# ECAP_ECAP_23100000h register map
Vendor: Texas Instruments
Peripheral module from a debugger description file (folder AM275x).
Registers are 32-bit, read-write, reset 0x0 unless marked. A register's access mark holds for its fields unless they carry their own. Offsets are as the file gives them; lines under a group give offsets from that group; [hi:lo] are bit positions; {n}, {i} and the like mark numbered series; 'fields as' and 'values as' point back to an identical list; <NAME> marks a mode.

## ecap
0x00 ECAP_TSCNT
  [31:0] TSCNT — Active 32 bit Counter register which is used as the Capture time-base Reset Source: vbus_rst_mod_g_rst_n
0x04 ECAP_CNTPHS
  [31:0] CNTPHS — Counter phase value register that can be programmed for phase Lag/Lead. This register shadows the ECAP_TSCNT register and is loaded into the ECAP_TSCNT register upon either a SYNCI event or software force via a control bit.Used to achieve phase control sync with respect to other ECAP and EPWM time-bases. Reset Source: vbus_rst_mod_g_rst_n
0x08 ECAP_CAP1
  [31:0] CAP1 — This register can be loaded (written) by:1. Time-Stamp (counter value) during a capture event.2. Software - may be useful for test purposes/initialisation.3. APRD shadow register (ECAP_CAP3) when used in APWM mode. Reset Source: vbus_rst_mod_g_rst_n
0x0C ECAP_CAP2
  [31:0] CAP2 — This register can be loaded (written) by:1. Time-Stamp (counter value) during a capture event.2. Software - may be useful for test purposes.3. ACMP shadow register (ECAP_CAP4) when used in APWM mode. Reset Source: vbus_rst_mod_g_rst_n
0x10 ECAP_CAP3
  [31:0] CAP3 — In CMP mode this is a time-stamp capture register.In APMW mode this is the period shadow (APER) register.User updates the PWM period value via this register.In this mode the ECAP_CAP3 (APRD) register shadows the ECAP_CAP1 register. Reset Source: vbus_rst_mod_g_rst_n
0x14 ECAP_CAP4
  [31:0] CAP4 — In CMP mode this is a time-stamp capture register.In APMW mode this is the compare shadow (ACMP) register.User updates the PWM Compare value via this register.In this mode the ECAP_CAP4 (ACMP) register shadows the ECAP_CAP2 register. Reset Source: vbus_rst_mod_g_rst_n
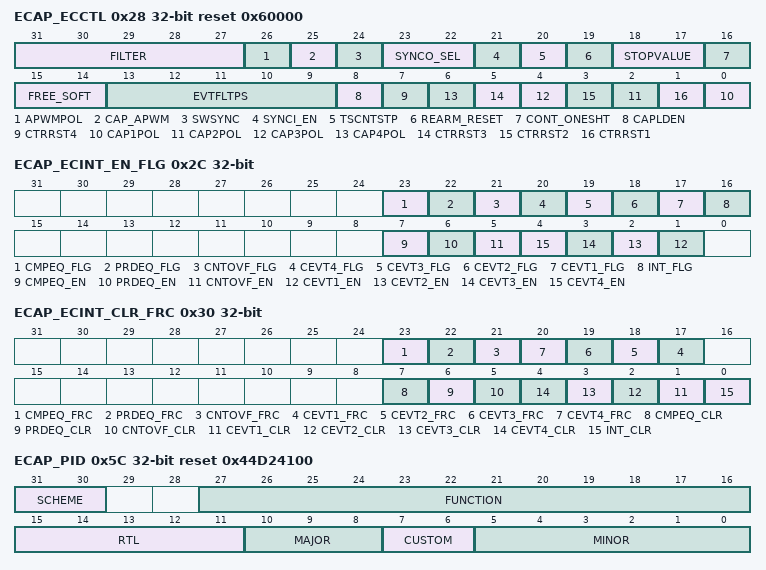
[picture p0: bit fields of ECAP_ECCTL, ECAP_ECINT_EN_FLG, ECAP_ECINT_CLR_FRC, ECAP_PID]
0x28 ECAP_ECCTL access not given reset 0x60000
  [31:27] FILTER ro — Reset Source: vbus_rst_mod_g_rst_n
  [26] APWMPOL rw — APWM Output Polarity Select:Note: This is applicable only in APWM operating mode. 0h Output is Active High (Compare value defines High time)1h Output is Active Low (Compare value defines Low time)
  [25] CAP_APWM rw — CAP/APWM Operating Mode Select: 0h ECAP module operates in Capture mode. This mode forces the following configuration: 1. Inhibits the ECAP_TSCNT register resets via PRD event. 2. Inhibits the Shadow loads on the ECAP_CAP1 and ECAP_CAP2 registers. 3. Permits user to enable the ECAP_CAP1 to ECAP_CAP4 register load. 4. CAPx/APWMx pin operates as a Capture input.1h ECAP module operates in APWM mode. This mode forces the following configuration: 1. Resets the ECAP_TSCNT register on PRD event (period boundary) 2. Permits Shadow loading on the ECAP_CAP1 and ECAP_CAP2 registers. 3. Disables loading of Time-stamps into the ECAP_CAP1 - ECAP_CAP4 registers 4. CAPx/APWMx pin operates as a APWM output.
  [24] SWSYNC — Software Forced Counter (ECAP_TSCNT) Synchronizing: 0h Writing a zero has no effect. Reading will always return a zero.1h Writing a one will force a ECAP_TSCNT shadow load of current ECAP module and any ECAP modules down-stream providing the SYNCO_SEL bits are 0h (access WTC)
  [23:22] SYNCO_SEL rw — SyncOut Select:Note: Selection PRD is meaningful only in APWM mode, however can still be chosen in CAP mode if user believes it to be useful. 0h Select SyncIn event to be the SyncOut signal (pass through)1h Select PRD event to be the SyncOut signal2h Disable SyncOut Signal3h Disable SyncOut Signal
  [21] SYNCI_EN rw — Counter (ECAP_TSCNT) SyncIn select mode: 0h Disable SyncIn option1h Enable Counter (ECAP_TSCNT) to be loaded from the ECAP_CNTPHS register upon either a SYNCI signal or a software force event.
  [20] TSCNTSTP rw — Counter Stop (freeze) Control: 0h Counter Stopped1h Counter Free Running
  [19] REARM_RESET — One-Shot Re-arming Control Wait for stop trigger: 0h Has no effect. Reading always returns a 0h1h Arms the One-Shot sequence: 1. Resets the Mod4 counter to zero. 2. Un-freezes the Mod4 counter. 3. Enables Capture Register Loads. (access WTC)
  [18:17] STOPVALUE rw — Stop Value for One-Shot Mode:This is the number (between 1 and 4) of captures allowed to occur before the ECAP_CAP1 through ECAP_CAP4 registers are frozen (capture sequence is stopped).Notes: [1] STOPVALUE is compared to Mod4 counter, when equal, two actions occur:1. Mod4 Counter is stopped (frozen)2. Capture register loads are inhibited[2] In one shot mode, further interrupt events are blocked until we re-arm, once the number of events captured has been reached. 0h Stop after Capture Event 11h Stop after Capture Event 22h Stop after Capture Event 33h Stop after Capture Event 4
  [16] CONT_ONESHT rw — Continuous or One-shot Mode Control (applicable only in Capture mode): 0h Operate in Continuous mode1h Operate in One-Shot mode
  [15:14] FREE_SOFT rw — Emulation Control 0h ECAP_TSCNT Counter stops immediately on emulation suspend1h ECAP_TSCNT Counter runs until = 0h3h ECAP_TSCNT Counter is unaffected by emulation suspend (Run Free)
  [13:9] EVTFLTPS rw — Event Filter Prescale Select: 0h Divide by 1 (no prescale, by-pass the prescaler)1Eh Divide by 601Fh Divide by 621h Divide by 22h Divide by 43h Divide by 64h Divide by 85h Divide by 10
  [8] CAPLDEN rw — Enable Loading of the ECAP_CAP1 to ECAP_CAP4 registers on a capture event: 0h Disable ECAP_CAP1 to ECAP_CAP4 register loads at capture event time.1h Enable ECAP_CAP1 to ECAP_CAP4 register loads at capture event time.
  [7] CTRRST4 rw — Counter Reset on Capture Event 4: 0h Do Not reset Counter on Capture Event 4 (absolute time stamp)1h Reset counter after Event 4 time-stamp has been captured (used in Difference mode operation)
  [2n-2] CAP{n}POL rw (n=1..4) — Capture Event {n} Polarity Select: 0h Capture event {n} triggered on a Rising Edge (RE)1h Capture event {n} triggered on a Falling Edge (FE)
  [5] CTRRST3 rw — Counter Reset on Capture Event 3: 0h Do not reset counter on Capture Event 3 (absolute time stamp)1h Reset counter after Event 3 time-stamp has been captured (used in difference mode operation)
  [3] CTRRST2 rw — Counter Reset on Capture Event 2: 0h Do not reset counter on Capture Event 2 (absolute time stamp)1h Reset Counter after Event 2 time-stamp has been captured (used in difference mode operation)
  [1] CTRRST1 rw — Counter Reset on Capture Event 1: 0h Do not reset counter on Capture Event 1 (absolute time stamp)1h Reset counter after Event 1 time-stamp has been captured (used in difference mode operation)
0x2C ECAP_ECINT_EN_FLG access per field
  [23] CMPEQ_FLG ro — Compare Equal Status Flag:Note: This flag is only active in APWM mode. 0h Indicates no event occurred1h Indicates the counter (ECAP_TSCNT) reached the Compare register value (ACMP)
  [22] PRDEQ_FLG ro — Period Equal Status Flag:Note: This flag is only active in APWM mode. 0h Indicates no event occurred1h Indicates the Counter (ECAP_TSCNT) reached the Period register value (APER) and was reset.
  [21] CNTOVF_FLG ro — Counter Overflow Status Flag:Note: This flag is active in CAP and APWM mode. 0h Indicates no event occurred.1h Indicates the Counter (ECAP_TSCNT) has made the transition from FFFF FFFFh to 0000 0000h
  [20] CEVT4_FLG ro — Capture Event 4 Status Flag:Note: This flag is only active in CAP mode. 0h Indicates no event occurred.1h Indicates the fourth event occurred at ECAPx pin.
  [19] CEVT3_FLG ro — Capture Event 3 Status Flag:Note: This flag is only active in CAP mode. 0h Indicates no event occurred.1h Indicates the third event occurred at ECAPx pin.
  [18] CEVT2_FLG ro — Capture Event 2 Status Flag:Note: This flag is only active in CAP mode. 0h Indicates no event occurred.1h Indicates the second event occurred at ECAPx pin.
  [17] CEVT1_FLG ro — Capture Event 1 Status Flag:Note: This flag is only active in CAP mode. 0h Indicates no event occurred.1h Indicates the first event occurred at ECAPx pin.
  [16] INT_FLG ro — Global Interrupt Status Flag: 0h Indicates no interrupt generated.1h Indicates that an interrupt was generated from one of the following events.
  [7] CMPEQ_EN rw — Compare Equal Interrupt Enable: 0h Disabled Compare Equal as an Interrupt source1h Enable Compare Equal as an Interrupt source
  [6] PRDEQ_EN rw — Period Equal Interrupt Enable: 0h Disabled Period Equal as an Interrupt source1h Enable Period Equal as an Interrupt source
  [5] CNTOVF_EN rw — Counter Overflow Interrupt Enable: 0h Disabled Counter Overflow as an Interrupt source1h Enable Counter Overflow as an Interrupt source
  [n] CEVT{n}_EN rw (n=1..4) — Capture Event {n} Interrupt Enable: 0h Disabled Capture Event {n} as an Interrupt source:1h Enable Capture Event {n} as an Interrupt source
0x30 ECAP_ECINT_CLR_FRC access not given
  [23] CMPEQ_FRC — Force Compare Equal: 0h No effect. Always reads back a 0h1h Writing a 1h to this bit will set the CMPEQ_FLG flag bit. (access W1TS)
  [22] PRDEQ_FRC — Force Period Equal: 0h No effect. Always reads back a 0.1h Writing a 1h to this bit will set the PRDEQ_FLG flag bit. (access W1TS)
  [21] CNTOVF_FRC — Force Counter Overflow: 0h No effect. Always reads back a 0.1h Writing a 1h to this bit will set the CNTOVF_FLG flag bit. (access W1TS)
  [n+16] CEVT{n}_FRC (n=1..4) — Force Capture Event {n}: 0h No effect. Always reads back a 0.1h Writing a 1h to this bit will set the CEVT{n}_FLG flag bit. (access W1TS)
  [7] CMPEQ_CLR — Compare Equal Status Flag: 0h No effect. Always reads back a 0.1h Writing a 1h will clear the CMPEQ_FLG flag condition. (access W1TC)
  [6] PRDEQ_CLR — Period Equal Status Flag: 0h No effect. Always reads back a 0.1h Writing a 1h will clear the PRDEQ_FLG flag condition. (access W1TC)
  [5] CNTOVF_CLR — Counter Overflow Status Flag: 0h No effect. Always reads back a 0.1h Writing a 1h will clear the CNTOVF_FLG flag condition. (access W1TC)
  [n] CEVT{n}_CLR (n=1..4) — Capture Event {n} Status Flag: 0h No effect. Always reads back a 0.1h Writing a 1h will clear the CEVT{n}_FLG flag condition. (access W1TC)
  [0] INT_CLR — Global Interrupt Clear Flag: 0h No effect. Always reads back a 0.1h Writing a 1h will clear the INT_FLG flag and enable further interrupts to be generated if any of the event flags are set to 1h. (access W1TC)
0x5C ECAP_PID ro reset 0x44D24100
  [31:30] SCHEME — Reset Source: vbus_rst_mod_g_rst_n
  [27:16] FUNCTION — Reset Source: vbus_rst_mod_g_rst_n
  [15:11] RTL — Reset Source: vbus_rst_mod_g_rst_n
  [10:8] MAJOR — Reset Source: vbus_rst_mod_g_rst_n
  [7:6] CUSTOM — Reset Source: vbus_rst_mod_g_rst_n
  [5:0] MINOR — Reset Source: vbus_rst_mod_g_rst_n
